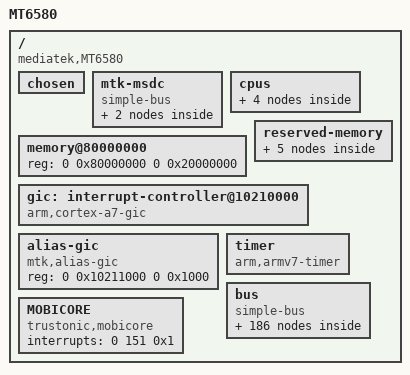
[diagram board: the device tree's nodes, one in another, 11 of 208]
/*
 * Mediatek's MT6580 SoC device tree source
 *
 * Copyright (c) 2013 MediaTek Co., Ltd.
 *              http://www.mediatek.com
 *
 */



/ {
	model = "MT6580";
	compatible = "mediatek,MT6580";
	interrupt-parent = <&gic>;
	#address-cells = <2>;
	#size-cells = <2>;

    /* chosen */
    chosen {
        bootargs = "console=tty0 console=ttyMT0,921600n1 root=/dev/ram initrd=0x84000000,0x400000 loglevel=8";
    };

    /* Do not put any bus before mtk-msdc, because it should be mtk-msdc.0 for partition device node usage */
    mtk-msdc {
        compatible = "simple-bus";
        #address-cells = <1>;
        #size-cells = <1>;
        ranges = <0 0 0 0xffffffff>;

        MSDC0@0x11120000 {
            compatible = "mediatek,MSDC0";
            reg = <0x11120000 0x10000  /* MSDC0_BASE   */
                   0x10001E84 0x2>;    /* FPGA PWR_GPIO, PWR_GPIO_EO */
            interrupts = <0 38 0x8>;
        };

        MSDC1@0x11130000 {
            compatible = "mediatek,MSDC1";
            reg = <0x11130000 0x10000  /* MSDC1_BASE   */
                   0x10001E84 0x2>;    /* FPGA PWR_GPIO, PWR_GPIO_EO */
            interrupts = <0 39 0x8>;
        };
    };

    cpus {
        #address-cells = <1>;
        #size-cells = <0>;

        cpu0: cpu@0 {
            device_type = "cpu";
            compatible = "arm,cortex-a7";
            reg = <0x000>;
            clock-frequency = <1700000000>;
        };

        cpu1: cpu@1 {
            device_type = "cpu";
            compatible = "arm,cortex-a7";
            reg = <0x001>;
            clock-frequency = <1700000000>;
        };

        cpu2: cpu@2 {
            device_type = "cpu";
            compatible = "arm,cortex-a7";
            reg = <0x002>;
            clock-frequency = <1700000000>;
        };

        cpu3: cpu@3 {
            device_type = "cpu";
            compatible = "arm,cortex-a7";
            reg = <0x003>;
            clock-frequency = <1700000000>;
        };
    };

    memory@80000000 {
        device_type = "memory";
        reg = <0 0x80000000 0 0x20000000>;
    };

    reserved-memory {
        #address-cells = <2>;
        #size-cells = <2>;
        ranges;

        reserve-memory-ccci_md1 {
            compatible = "reserve-memory-ccci_md1";
            no-map;
            size = <0 0x1800000>;       /* MD ROM + RAM + SMEM */
            alignment = <0 0x2000000>;  /* 32M alignment */
            alloc-ranges = <0 0x80000000 0 0x80000000>;
        };

        pstore-reserved-memory {
            compatible = "pstore-reserve-memory";
            reg = <0 0x83f10000 0 0xe0000>;
        };

		mrdump-reserved-memory {
			compatible = "mrdump-reserved-memory";
			reg = <0 0x81F00000 0 0x2000>;
		};

		preloader-reserved-memory {
			compatible = "mrdump-reserved-memory";
			reg = <0 0x82000000 0 0x200000>;
		};

		lk-reserved-memory {
			compatible = "mrdump-reserved-memory";
			reg = <0 0x81E00000 0 0x100000>;
		};
    };

    gic: interrupt-controller@10210000 {
        compatible = "arm,cortex-a7-gic";
        #interrupt-cells = <3>;
        #address-cells = <0>;
        interrupt-controller;
        reg = <0 0x10211000 0 0x1000>,
              <0 0x10212000 0 0x1000>,
              <0 0x10200100 0 0x1000>;
       interrupts = <1 9 0xf04>;
    };

    /* redundent gic device node to support other module's who want to use same query flow to get basic GIC info. EX: eint might want to know max GIC nr by */
    alias-gic {
        compatible = "mtk,alias-gic";
	reg = <0 0x10211000 0 0x1000>; /* only dist base is enough */
    };

    timer {
        compatible = "arm,armv7-timer";
        interrupts = <1 13 0x8>,
        <1 14 0x8>,
        <1 11 0x8>,
        <1 10 0x8>;
        clock-frequency = <13000000>;
    };

	bus {
		compatible = "simple-bus";
		#address-cells = <1>;
		#size-cells = <1>;
		ranges = <0 0 0 0xffffffff>;

		TOPCKGEN@0x10000000 {
			compatible = "mediatek,TOPCKGEN";
			reg = <0x10000000 0x1000>;
		};

		INFRACFG_AO@0x10001000 {
			compatible = "mediatek,INFRACFG_AO";
			reg = <0x10001000 0x1000>;
		};

        BAT_METTER {
            compatible = "mediatek,bat_meter";
        };
        
        BAT_NOTIFY {
            compatible = "mediatek,bat_notify";
        };

		BATTERY {
			compatible = "mediatek,battery";
		};


		KP@0x10002000 {
			compatible = "mediatek,KP";
			reg = <0x10002000 0x1000>;
			interrupts = <0 109 0x2>;
		};

		PERICFG@0x10003000 {
			compatible = "mediatek,PERICFG";
			reg = <0x10003000 0x1000>;
		};

		RESERVED@0x10004000 {
			compatible = "mediatek,RESERVED";
			reg = <0x10004000 0x1000>;
		};

		GPIO@0x10005000 {
			compatible = "mediatek,GPIO";
			reg = <0x10005000 0x1000>;
		};

		SLEEP@0x10006000 {
			compatible = "mediatek,SLEEP";
			reg = <0x10006000 0x1000>;
			interrupts = <0 88 0x8>,
				     <0 89 0x8>,
				     <0 90 0x8>,
				     <0 91 0x8>;
		};

		TOPRGU@0x10007000 {
			compatible = "mediatek,TOPRGU";
			reg = <0x10007000 0x1000>;
			interrupts = <0 157 0x2>;
		};

		APXGPT@0x10008000 {
			compatible = "mediatek,APXGPT";
			reg = <0x10008000 0x1000>;
			interrupts = <0 92 0x8>;
			clock-frequency = <13000000>;
		};

		EFUSEC@0x10009000 {
			compatible = "mediatek,EFUSEC";
			reg = <0x10009000 0x1000>;
		};

		SEJ@0x1000A000 {
			compatible = "mediatek,SEJ";
			reg = <0x1000A000 0x1000>;
			interrupts = <0 110 0x0>;
		};

		DBG_DEBUG {
			compatible = "mediatek,DBG_DEBUG";
			num = <4>;
			reg = <0x10170000 0x2000
				0x10172000 0x2000
				0x10174000 0x2000
				0x10176000 0x2000>;
                };

		eintc: EINTC@0x1000B000 {
			compatible = "mtk,mt-eic";
			reg = <0x1000B000 0x1000>;
			interrupts = <0 94 0x4>;

			#interrupt-cells = <2>;
			interrupt-controller;

			max_eint_num = <26>;
			mapping_table_entry = <83>;
			mapping_table = <0 0>, /* <gpio_pin, eint_pin> */
					<1 1>,
					<2 2>,
					<3 3>,
					<4 4>,
					<5 5>,
					<6 6>,
					<7 7>,
					<8 8>,
					<9 9>,
					<10 10>,
					<11 11>,
					<12 12>,
					<13 13>,
					<14 14>,
					<15 15>,
					<16 0>,
					<17 1>,
					<18 2>,
					<19 3>,
					<20 4>,
					<21 5>,
					<22 6>,
					<23 7>,
					<24 8>,
					<25 9>,
					<26 10>,
					<27 11>,
					<28 12>,
					<29 13>,
					<30 14>,
					<31 15>,
					<32 0>,
					<33 1>,
					<34 2>,
					<35 3>,
					<36 4>,
					<37 5>,
					<38 6>,
					<39 7>,
					<40 8>,
					<41 9>,
					<42 10>,
					<43 11>,
					<44 12>,
					<45 13>,
					<46 14>,
					<47 15>,
					<48 0>,
					<49 1>,
					<50 2>,
					<51 3>,
					<52 3>,
					<53 4>,
					<54 5>,
					<55 6>,
					<56 7>,
					<57 8>,
					<58 10>,
					<59 11>,
					<60 12>,
					<61 13>,
					<62 14>,
					<63 15>,
					<64 0>,
					<65 1>,
					<66 2>,
					<67 3>,
					<68 16>,
					<69 4>,
					<70 5>,
					<71 6>,
					<72 7>,
					<73 8>,
					<74 9>,
					<75 10>,
					<76 11>,
					<77 12>,
					<78 13>,
					<81 0>,
					<82 1>,
					<83 2>,
					<84 3>;

			/* the number of gpio/eint mapping might be affected by built-in eint */
			builtin_entry = <11>;
			/* gpio, built-in func mode, built-in eint */
			builtin_mapping = <0 3 20>, /* USB IDDIG & USB VBUS */
					   <1 3 18>,
					   <7 4 20>,
					   <8 4 18>,
					   <9 3 20>,
					   <10 3 18>,
					   <24 5 20>,
					   <25 5 18>,
					   <77 2 20>,
					   <78 2 18>,
					   <13 1 17>; /* PMIC */
		};

		AP_CCIF0@0x1000C000 {
			compatible = "mediatek,AP_CCIF0";
			reg = <0x1000C000 0x1000>,   /*AP_CCIF_BASE*/
				<0x1000D000 0x1000>; /*MD_CCIF_BASE*/
			interrupts = <0 93 0x8>,    /* CCIF0 IRQ */
				<0 152 0x2>;     /* MD WDT IRQ */
			ccif0,major = <184>;
			ccif0,minor_base = <0>;
			ccif0,capability = <2>;
			md_smem_size = <0x200000>; //md share memory size
		};

		MD_CCIF0@0x1000D000 {
			compatible = "mediatek,MD_CCIF0";
			reg = <0x1000D000 0x1000>;
		};

		MCUSYS_CFGREG@0x1020000 {
			compatible = "mediatek,MCUSYS_CFGREG_BASE";
			reg = <0x1020000 0x200>;
		};

		AP_MD_DBGMODE_CFGREG@0x1011A010 {
			compatible = "mediatek,AP_MD_DBGMODE_CFGREG";
			reg = <0x1011A010 0x200>;
		};

		AES@0x1000E000 {
			compatible = "mediatek,AES";
			reg = <0x1000E000 0x1000>;
		};

		PWRAP@0x1000F000 {
			compatible = "mediatek,PWRAP";
			reg = <0x1000F000 0x1000>;
			interrupts = <0 108 0x0>;
		};

		DEVAPC_AO@0x10010000 {
			compatible = "mediatek,DEVAPC_AO";
			reg = <0x10010000 0x1000>;
		};

		MIPI_CONFG@0x10011000 {
			compatible = "mediatek,MIPI_CONFG";
			reg = <0x10011000 0x1000>;
		};

		INFRA_MBIST@0x10012000 {
			compatible = "mediatek,INFRA_MBIST";
			reg = <0x10012000 0x1000>;
		};

		RESERVED@0x10013000 {
			compatible = "mediatek,RESERVED";
			reg = <0x10013000 0x1000>;
		};

		IOCFG_T@0x10014000 {
			compatible = "mediatek,IOCFG_T";
			reg = <0x10014000 0x1000>;
		};

		IOCFG_B@0x10015000 {
			compatible = "mediatek,IOCFG_B";
			reg = <0x10015000 0x1000>;
		};

		IOCFG_L@0x10016000 {
			compatible = "mediatek,IOCFG_L";
			reg = <0x10016000 0x1000>;
		};

		IOCFG_R@0x10017000 {
			compatible = "mediatek,IOCFG_R";
			reg = <0x10017000 0x1000>;
		};

		APMIXED@0x10018000 {
			compatible = "mediatek,APMIXED";
			reg = <0x10018000 0x1000>;
		};

		MCUCFG@0x10200000 {
			compatible = "mediatek,MCUCFG";
			reg = <0x10200000 0x1000>;
		};

		INFRACFG@0x10201000 {
			compatible = "mediatek,INFRACFG";
			reg = <0x10201000 0x1000>;
		};

                SYS_CIRQ@0x10202000 {
                        compatible = "mediatek,SYS_CIRQ";
                        reg = <0x10202000 0x1000>;
                        interrupts = <0 158 0x8>;
                        cirq_num = <126>;
                        spi_start_offset = <32>;
                };


		M4U@0x10203000 {
                        cell-index = <0>;
			compatible = "mediatek,M4U";
			reg = <0x10203000 0x1000>;
                        interrupts = <0 81 0x8>;
		};

		DEVAPC@0x10204000 {
			compatible = "mediatek,DEVAPC";
			reg = <0x10204000 0x1000>;
			interrupts = <0 74 0x8>;
		};

		EMI@0x10205000 {
			compatible = "mediatek,EMI";
			reg = <0x10205000 0x1000>;
			interrupts = <0 76 0x4>;
		};
		
		DRAMC_NAO@0x10206000 {
			compatible = "mediatek,DRAMC_NAO";
			reg = <0x10206000 0x1000>;
		};

		DRAMC0@0x10207000 {
			compatible = "mediatek,DRAMC0";
			reg = <0x10207000 0x1000>;
		};

		DDRPHY@0x10208000 {
			compatible = "mediatek,DDRPHY";
			reg = <0x10208000 0x1000>;
		};

		SRAMROM@0x10209000 {
			compatible = "mediatek,SRAMROM";
			reg = <0x10209000 0x1000>;
		};

		GCE@0x1020A000 {
			compatible = "mediatek,GCE";
			reg = <0x1020A000 0x1000>;
			interrupts = <0 85 0x8>,
			             <0 86 0x8>;
		};

		BUS_DBG@0x1020B000 {
			compatible = "mediatek,BUS_DBG";
			reg = <0x1020B000 0x1000>;
			interrupts = <0 73 0x8>;
			two_stage_timeout = <1>;
		};

		TRNG@0x1020C000 {
			compatible = "mediatek,TRNG";
			reg = <0x1020C000 0x1000>;
			interrupts = <0 87 0x8>;
		};

		MCUCFG_BIU@0x1020D000 {
			compatible = "mediatek,MCUCFG_BIU";
			reg = <0x1020D000 0x1000>;
		};


		DBGSYS_DEM@0x1011A000 {
			compatible = "mediatek,DBGSYS_DEM";
			reg = <0x1011A000 0x1000>;
		};

		DBGSYS_CTI@0x10112000 {
			compatible = "mediatek,DBGSYS_CTI";
			reg = <0x10112000 0x1000>;
		};

		DBGSYS_DAPROM@0x10110000 {
			compatible = "mediatek,DBGSYS_DAPROM";
			reg = <0x10110000 0x1000>;
		};

		DBGSYS_CPU@0x10160000 {
			compatible = "mediatek,DBGSYS_CPU";
			reg = <0x10160000 0x20000>;
		};

		DBGSYS_MDSYS@0x10120000 {
			compatible = "mediatek,DBGSYS_MDSYS";
			reg = <0x10120000 0x10000>;
		};
		CQDMA@0x1020AC00 {
			compatible = "mediatek,CQDMA";
			reg = <0x1020AC00 0x1000>;
			interrupts = <0 77 0x8>;
			nr_channel = <1>;
		};
		AP_DMA@0x11000000 {
			compatible = "mediatek,AP_DMA";
			reg = <0x11000000 0x1000>;
			interrupts = <0 48 0x8>;
		};

		NFI@0x11001000 {
			compatible = "mediatek,NFI";
			reg = <0x11001000 0x1000>;
			interrupts = <0 79 0x8>;
		};

		NFIECC@0x11002000 {
			compatible = "mediatek,NFIECC";
			reg = <0x11002000 0x1000>;
			interrupts = <0 78 0x8>;
		};

		AUXADC@0x11003000 {
			compatible = "mediatek,AUXADC";
			reg = <0x11003000 0x1000>;
			interrupts = <0 35 0x2>;
		};

		FHCTL@0x11004000 {
			compatible = "mediatek,FHCTL";
			reg = <0x11004000 0x1000>;
		};

		AP_UART0@0x11005000 {
            cell-index = <0>;
			compatible = "mediatek,AP_UART0";
			reg = <0x11005000 0x1000>;
			interrupts = <0 44 0x8>;
		};

		AP_UART1@0x11006000 {
            cell-index = <1>;
			compatible = "mediatek,AP_UART1";
			reg = <0x11006000 0x1000>;
			interrupts = <0 45 0x8>;
		};
	
        AP_DMA_UART0_TX@0x11000480 {
            compatible = "mediatek,AP_DMA_UART0_TX";
            reg = <0x11000480 0x80>;
            interrupts = <0 56 0x8>;
        };

        AP_DMA_UART0_RX@0x11000500 {
            compatible = "mediatek,AP_DMA_UART0_RX";
            reg = <0x11000500 0x80>;
            interrupts = <0 57 0x8>;
        };

        AP_DMA_UART1_TX@0x11000580 {
            compatible = "mediatek,AP_DMA_UART1_TX";
            reg = <0x11000580 0x80>;
            interrupts = <0 58 0x8>;
        };

        AP_DMA_UART1_RX@0x11000600 {
            compatible = "mediatek,AP_DMA_UART1_RX";
            reg = <0x11000600 0x80>;
            interrupts = <0 59 0x8>;
        };


		PWM@0x11008000 {
			compatible = "mediatek,PWM";
			reg = <0x11008000 0x1000>;
			interrupts = <0 36 0x8>;
		};

		i2c0: I2C0@0x11009000 {
			compatible = "mediatek,I2C0";
			cell-index = <0>;
			reg = <0x11009000 0x1000>;
			#address-cells = <1>;
			#size-cells = <0>;
			interrupts = <0 40 0x8>,
				<0 50 0x8>;
		};

		i2c1: I2C1@0x1100A000 {
			compatible = "mediatek,I2C1";
			cell-index = <1>;
			reg = <0x1100A000 0x1000>;
			#address-cells = <1>;
			#size-cells = <0>;
			interrupts = <0 41 0x8>,
				<0 51 0x8>;
		};

		i2c2: I2C2@0x1100B000 {
			compatible = "mediatek,I2C2";
			cell-index = <2>;
			reg = <0x1100B000 0x1000>;
			#address-cells = <1>;
			#size-cells = <0>;
			interrupts = <0 42 0x8>,
				<0 52 0x8>;
		};

		SPI@0x1100C000 {
			compatible = "mediatek,SPI";
			cell-index = <0>;
			spi-padmacro = <0>;
			/* spi-cs=<0 1>; */
			/* spi-clk=<1 1>; */
			/* spi-mo=<2 1>; */
			/* spi-mi=<3 1>; */
			reg = <0x1100C000 0x1000>;
			interrupts = <0 64 0x8>;
		};

		THERM_CTRL@0x1100D000 {
			compatible = "mediatek,THERM_CTRL";
			reg = <0x1100D000 0x1000>;
			interrupts = <0 37 0x8>;
		};


		AP_DMA_BTIF_TX@0x11000380 {
			compatible = "mediatek,AP_DMA_BTIF_TX";
			reg = <0x11000380 0x80>;
			interrupts = <0 54 0x8>;
		};

		AP_DMA_BTIF_RX@0x11000400 {
			compatible = "mediatek,AP_DMA_BTIF_RX";
			reg = <0x11000400 0x80>;
			interrupts = <0 55 0x8>;
		};

		BTIF@0x1100C000 {
			compatible = "mediatek,BTIF";
			reg = <0x1100E000 0x1000>;
			interrupts = <0 67 0x8>;
		};

		mt3326-gps@0xffffffff {
			compatible = "mediatek,mt3326-gps";
		};


		BTCVSD@0x18000000 {
			compatible = "mediatek,audio_bt_cvsd";
			reg = <0x18000000 0x1000>, /*CVSD REG_BASE*/
			      <0x18080000 0x1000>; /*CVSD SRAM*/
			interrupts = <0 153 0x8>;
		};

	    CONSYS@0x18070000 {
	        compatible = "mediatek,CONSYS";
	        reg = <0x18070000 0x0200>,  /*CONN_MCU_CONFIG_BASE      */
	              <0x10007000 0x0100>,  /*AP_RGU_BASE               */
	              <0x10000000 0x2000>,  /*TOPCKGEN_BASE             */
	              <0x10006000 0x1000>,  /*SPM_BASE                  */
	              <0x10005000 0x1000>;  /*DA_XOBUF                  */
		      interrupts = <0 154 0x8>, /*BGF_EINT                  */
		      			   <0 156 0x8>; /*WDT_EINT                  */
	    };

		WIFI@0x180F0000 {
			compatible = "mediatek,WIFI";
			reg = <0x180F0000 0x005C>;
			interrupts = <0 155 0x8>;
		};
		DISP_PWM@0x1100F000 {
			compatible = "mediatek,DISP_PWM";
			reg = <0x1100F000 0x1000>;
			interrupts = <0 33 0x8>;
		};

 		USB0@0x11100000 {
			compatible = "mediatek,USB0";
			cell-index = <0>;
			reg = <0x11100000 0x10000>,
						<0x11110000 0x10000>;
			interrupts = <0 32 0x8>;
			mode = <2>;
			multipoint = <1>;
			dyn_fifo = <1>;
			soft_con = <1>;
			dma = <1>;
			num_eps = <16>;
			dma_channels = <8>;
			iddig_gpio = <9 3>;
			drvvbus_gpio = <10 3>;
		};

		AUDIO@0x11140000 {
			compatible = "mediatek,AUDIO";
			reg = <0x11140000 0x10000>;
			interrupts = <0 80 0x8>;
		};
		
		MT_SOC_DL1_PCM@0x11140000 {
			compatible = "mediatek,mt_soc_pcm_dl1";
			reg = <0x11140000 0x1000>;
			interrupts = <0 80 0x8>;
			audclk-gpio = <26 0>;
			audmiso-gpio = <28 0>;
			audmosi-gpio = <27 0>;
		};

		MT_SOC_UL1_PCM@0x11140000 {
			compatible = "mediatek,mt_soc_pcm_capture";	
		};

		MT_SOC_VOICE_MD1@0x11140000 {
			compatible = "mediatek,mt_soc_pcm_voice_md1";	
		};

		MT_SOC_HDMI_PCM@0x11140000 {
			compatible = "mediatek,mt_soc_pcm_hdmi";	
		};

		MT_SOC_ULDLLOOPBACK_PCM@0x11140000 {
			compatible = "mediatek,mt_soc_pcm_uldlloopback";	
		};

		MT_SOC_I2S0_PCM@0x11140000 {
			compatible = "mediatek,mt_soc_pcm_dl1_i2s0";	
		};

		MT_SOC_MRGRX_PCM@0x11140000 {
			compatible = "mediatek,mt_soc_pcm_mrgrx";	
		};

		MT_SOC_MRGRX_AWB_PCM@0x11140000 {
			compatible = "mediatek,mt_soc_pcm_mrgrx_awb";	
		};

		MT_SOC_FM_I2S_PCM@0x11140000 {
			compatible = "mediatek,mt_soc_pcm_fm_i2s";	
		};

		MT_SOC_FM_I2S_AWB_PCM@0x11140000 {
			compatible = "mediatek,mt_soc_pcm_fm_i2s_awb";	
		};

		MT_SOC_I2S0DL1_PCM@0x11140000 {
			compatible = "mediatek,mt_soc_pcm_dl1_i2s0Dl1";	
		};	

		MT_SOC_DL1_AWB_PCM@0x11140000 {
			compatible = "mediatek,mt_soc_pcm_dl1_awb";	
		};

		MT_SOC_VOICE_MD1_BT@0x11140000 {
			compatible = "mediatek,mt_soc_pcm_voice_md1_bt";	
		};

		MT_SOC_VOIP_BT_OUT@0x11140000 {
			compatible = "mediatek,mt_soc_pcm_dl1_bt";	
		};

		MT_SOC_VOIP_BT_IN@0x11140000 {
			compatible = "mediatek,mt_soc_pcm_bt_dai";	
		};

		MT_SOC_TDMRX_PCM@0x11140000 {
			compatible = "mediatek,mt_soc_tdm_capture";	
		};

		MT_SOC_FM_MRGTX_PCM@0x11140000 {
			compatible = "mediatek,mt_soc_pcm_fmtx";	
		};

		MT_SOC_UL2_PCM@0x11140000 {
			compatible = "mediatek,mt_soc_pcm_capture2";	
		};

		MT_SOC_I2S0_AWB_PCM@0x11140000 {
			compatible = "mediatek,mt_soc_pcm_i2s0_awb";	
		};	

		MT_SOC_VOICE_MD2@0x11140000 {
			compatible = "mediatek,mt_soc_pcm_voice_md2";	
		};

		MT_SOC_ROUTING_PCM@0x11140000 {
			compatible = "mediatek,mt_soc_pcm_routing";	
		};

		MT_SOC_VOICE_MD2_BT@0x11140000 {
			compatible = "mediatek,mt_soc_pcm_voice_md2_bt";	
		};	

		MT_SOC_HP_IMPEDANCE_PCM@0x11140000 {
			compatible = "mediatek,Mt_soc_pcm_hp_impedance";	
		};		

		MT_SOC_CODEC_NAME@0x11140000 {
			compatible = "mediatek,mt_soc_codec_63xx";	
		};		

		MT_SOC_DUMMY_PCM@0x11140000 {
			compatible = "mediatek,mt_soc_pcm_dummy";	
		};

		MT_SOC_CODEC_DUMMY_NAME@0x11140000 {
			compatible = "mediatek,mt_soc_codec_dummy";	
		};

		MT_SOC_ROUTING_DAI_NAME@0x11140000 {
			compatible = "mediatek,mt_soc_dai_routing";	
		};

		MT_SOC_DAI_NAME@0x11140000 {
			compatible = "mediatek,mt_soc_dai_stub";	
		};
		
		AHB_MOM@0x11150000 {
			compatible = "mediatek,AHB_MOM";
			reg = <0x11150000 0x10000>;
		};

		MDI@0x11160000 {
			compatible = "mediatek,MDI";
			reg = <0x11160000 0x10000>;
		};

		G3D_CONFIG@0x13000000 {
			compatible = "mediatek,G3D_CONFIG";
			reg = <0x13000000 0x1000>;
		};

		MALI@0x13010000 {
			compatible = "mediatek,MALI";
			reg = <0x13010000 0x10000>;
		};

		MMSYS_CONFIG@0x14000000 {
			compatible = "mediatek,MMSYS_CONFIG";
			reg = <0x14000000 0x1000>;
			interrupts = <0 132 0x8>;
		};

		MDP_RDMA@0x14001000 {
			compatible = "mediatek,MDP_RDMA";
			reg = <0x14001000 0x1000>;
			interrupts = <0 113 0x8>;
		};

		MDP_RSZ0@0x14002000 {
			compatible = "mediatek,MDP_RSZ0";
			reg = <0x14002000 0x1000>;
			interrupts = <0 114 0x8>;
		};

		MDP_RSZ1@0x14003000 {
			compatible = "mediatek,MDP_RSZ1";
			reg = <0x14003000 0x1000>;
			interrupts = <0 115 0x8>;
		};

		MDP_WDMA@0x14004000 {
			compatible = "mediatek,MDP_WDMA";
			reg = <0x14004000 0x1000>;
			interrupts = <0 117 0x8>;
		};

		MDP_WROT@0x14005000 {
			compatible = "mediatek,MDP_WROT";
			reg = <0x14005000 0x1000>;
			interrupts = <0 118 0x8>;
		};

		MDP_TDSHP@0x14006000 {
			compatible = "mediatek,MDP_TDSHP";
			reg = <0x14006000 0x1000>;
			interrupts = <0 116 0x8>;
		};
		DISPSYS@0x14007000 {
			compatible = "mediatek,DISPSYS";
			reg = <0x14000000 0x1000>,  /*DISP_SYS     */
			      <0x14007000 0x1000>,  /*DISP_OVL0     */
			      <0x14008000 0x1000>,  /*DISP_OVL1     */
			      <0x14009000 0x1000>,  /*DISP_RDMA0     */
			      <0x1400A000 0x1000>,  /*DISP_RDMA1     */
			      <0x1400B000 0x1000>,  /*DISP_WDMA0     */
			      <0x1400C000 0x1000>,  /*DISP_COLOR     */
			      <0x1400D000 0x1000>,  /*DISP_CCORR     */
			      <0x1400E000 0x1000>,  /*DISP_AAL       */
			      <0x1400F000 0x1000>,  /*DISP_GAMMA     */
			      <0x14010000 0x1000>,  /*DISP_DITHER    */
			      <0x14011000 0x1000>,  /*DISP_UFOE      */
			      <0x14012000 0x1000>,  /*DISP_DSI0       */
			      <0x14013000 0x1000>,  /*DISP_DPI0      */
			      <0x1100F000 0x1000>,  /*DISP_PWM       */
			      <0x14015000 0x1000>,  /*DISP_MUTEX     */
			      <0x14016000 0x1000>,  /*DISP_SMI_LARB0 */
			      <0x14017000 0x1000>,  /*DISP_SMI_COMMOM*/
			      <0x14018000 0x1000>;      /*MIPITX0,real chip would use this:<0x14018000 0x1000>;*/


      interrupts = <0 0 8>, /*DISP_SYS */
                   <0 119 8>, /*DISP_OVL0 */
                   <0 0 8>, /*DISP_OVL1 */
                   <0 121 8>, /*DISP_RDMA0 */
                   <0 0 8>, /*DISP_RDMA1 */
                   <0 123 8>, /*DISP_WDMA0 */
                   <0 124 8>, /*DISP_COLOR */
                   <0 0 8>, /*DISP_CCORR */
                   <0 126 8>, /*DISP_AAL */
                   <0 127 8>, /*DISP_GAMMA */
                   <0 128 8>, /*DISP_DITHER */
                   <0 0 8>, /*DISP_UFOE */
                   <0 130 8>, /*DISP_DSI0 */
                   <0 0 8>, /*DISP_DPI0 */
                   <0 0 8>, /*DISP_PWM */
                   <0 112 8>, /*DISP_MUTEX */
                   <0 0 8>, /*DISP_SMI_LARB0 */
                   <0 0 8>, /*DISP_SMI_COMMOM*/
                   <0 0 8>; /*MIPITX0*/
        	};

		DISP_OVL0@0x14007000 {
			compatible = "mediatek,DISP_OVL0";
			reg = <0x14007000 0x1000>;
			interrupts = <0 119 0x8>;
		};

		DISP_OVL1@0x14008000 {
			compatible = "mediatek,DISP_OVL1";
			reg = <0x14008000 0x1000>;
		};

		DISP_RDMA0@0x14009000 {
			compatible = "mediatek,DISP_RDMA0";
			reg = <0x14009000 0x1000>;
			interrupts = <0 121 0x8>;
		};

		DISP_RDMA1@0x1400A000 {
			compatible = "mediatek,DISP_RDMA1";
			reg = <0x1400A000 0x1000>;
		};

		DISP_WDMA@0x1400B000 {
			compatible = "mediatek,DISP_WDMA";
			reg = <0x1400B000 0x1000>;
			interrupts = <0 123 0x8>;
		};

		DISP_COLOR@0x1400C000 {
			compatible = "mediatek,DISP_COLOR";
			reg = <0x1400C000 0x1000>;
			interrupts = <0 124 0x8>;
		};

		DISP_CCORR@0x1400D000 {
			compatible = "mediatek,DISP_CCORR";
			reg = <0x1400D000 0x1000>;
		};

		DISP_AAL@0x1400E000 {
			compatible = "mediatek,DISP_AAL";
			reg = <0x1400E000 0x1000>;
			interrupts = <0 126 0x8>;
		};

		DISP_GAMMA@0x1400F000 {
			compatible = "mediatek,DISP_GAMMA";
			reg = <0x1400F000 0x1000>;
			interrupts = <0 127 0x8>;
		};

		DISP_DITHER@0x14010000 {
			compatible = "mediatek,DISP_DITHER";
			reg = <0x14010000 0x1000>;
			interrupts = <0 128 0x8>;
		};

		DISP_UFOE@0x14011000 {
			compatible = "mediatek,DISP_UFOE";
			reg = <0x14011000 0x1000>;
		};

		DSI@0x14012000 {
			compatible = "mediatek,DSI";
			reg = <0x14012000 0x1000>;
		};

		DPI@0x14013000 {
			compatible = "mediatek,DPI";
			reg = <0x14013000 0x1000>;
		};

		
		PTP_FSM@0x1100D000 {
			compatible = "mediatek,PTP_FSM";
			reg = <0x1100D000 0x1000>;
			interrupts = <0 43 0x8>;
		};
		
		MM_MUTEX@0x14015000 {
			compatible = "mediatek,MM_MUTEX";
			reg = <0x14015000 0x1000>;
			interrupts = <0 112 0x8>;
		};

		SMI_LARB0@0x14016000 {
			compatible = "mediatek,SMI_LARB0";
			reg = <0x14016000 0x1000>;
			interrupts = <0 133 0x8>;
		};

		SMI_COMMON@0x14017000 {
			compatible = "mediatek,SMI_COMMON";
			reg = <0x14017000 0x1000>,  /* SMI_COMMON */
				<0x14016000 0x1000>,  /* LARB 0 */ 
				<0x15001000 0x1000>;  /* LARB 1 */
		};

		MIPI_TX_CONFIG@0x14018000 {
			compatible = "mediatek,MIPI_TX_CONFIG";
			reg = <0x14018000 0x1000>;
		};

                ISPSYS@0x15000000 {
			compatible = "mediatek,ISPSYS";
			reg = <0x15004000 0x9000>,  /*ISP_ADDR      */
				<0x15000000 0x10000>,  /*IMGSYS_CONFIG_ADDR      */
				<0x10011000 0x4000>,  /*MIPI_ANA_ADDR      */
				<0x10017000 0x1000>;
			interrupts = <0 142 0x8>, /* SENINF */
                                     <0 139 0x8>; /* CAM0 */
		};
                /*for sysram dev and pipemgr dev*/
                ISP_SYSR@0x15000000 {
			compatible = "mediatek,ISP_SYSR";
		};
                ISP_PIPEM@0x15000000 {
			compatible = "mediatek,ISP_PIPEM";
		};
		KD_CAMERA_HW1@0x15008000 {
                        compatible = "mediatek,CAMERA_HW";
                        reg = <0x15008000 0x1000>;  /* SENINF_ADDR */
                };
                KD_CAMERA_HW2@0x15008000 {
                        compatible = "mediatek,CAMERA_HW2";
                        reg = <0x15008000 0x1000>;  /* SENINF_ADDR */
                };
		SENINF_TOP@0x15008000 {
			compatible = "mediatek,SENINF_TOP";
			reg = <0x15008000 0x1000>;
			interrupts = <0 142 0x8>;
		};

		CAM_0@0x15004000 {
			compatible = "mediatek,CAM_0";
			reg = <0x15004000 0x1000>;
			interrupts = <0 139 0x8>;
		};

		CAM_1@0x15005000 {
			compatible = "mediatek,CAM_1";
			reg = <0x15005000 0x1000>;
		};

		VENC@0x15009000 {
			compatible = "mediatek,VENC";
			reg = <0x15009000 0x1000>;
			interrupts = <0 138 0x8>;
		};

		VDEC@0x1500B000 {
			compatible = "mediatek,VDEC";
			reg = <0x1500B000 0x1000>;
			interrupts = <0 137 0x8>;
		};

		SMI_LARB1@0x15001000 {
			compatible = "mediatek,SMI_LARB1";
			reg = <0x15001000 0x1000>;
			interrupts = <0 136 0x8>;
		};

		IMGSYS_CONFIG@0x15000000 {
			compatible = "mediatek,IMGSYS_CONFIG";
			reg = <0x15000000 0x1000>;
		};

		hwmsensor@0 {
			compatible = "mediatek,hwmsensor";
		};
		gsensor@0 {
			compatible = "mediatek,gsensor";
		};
		als_ps@0 {
			compatible = "mediatek,als_ps";
		};
		m_acc_pl@0 {
			compatible = "mediatek,m_acc_pl";
		};
		m_alsps_pl@0 {
			compatible = "mediatek,m_alsps_pl";
		};
		sensorHub@0 {
			compatible = "mediatek,sensorHub";
		};
		shf@0 {
			compatible = "mediatek,shf";
		};
		m_batch_pl@0 {
			compatible = "mediatek,m_batch_pl";
		};
		gyroscope@0 {
			compatible = "mediatek,gyroscope";
		};
		m_gyro_pl@0 {
			compatible = "mediatek,m_gyro_pl";
		};
		barometer@0 {
			compatible = "mediatek,barometer";
		};
		m_baro_pl@0 {
			compatible = "mediatek,m_baro_pl";
		};
		msensor@0 {
			compatible = "mediatek,msensor";
		};
		m_mag_pl@0 {
			compatible = "mediatek,m_mag_pl";
		};
		orientation@0 {
			compatible = "mediatek,orientation";
		};
		pedometer@0 {
			compatible = "mediatek,pedometer";
		};
		m_pdr_pl@0 {
			compatible = "mediatek,m_pdr_pl";
		};
		step_counter@0 {
			compatible = "mediatek,step_counter";
		};
		m_step_c_pl@0 {
			compatible = "mediatek,m_step_c_pl";
		};
		in_pocket@0 {
			compatible = "mediatek,in_pocket";
		};
		m_inpk_pl@0 {
			compatible = "mediatek,m_inpk_pl";
		};
		shake@0 {
			compatible = "mediatek,shake";
		};
		m_shk_pl@0 {
			compatible = "mediatek,m_shk_pl";
		};
		face_down@0 {
			compatible = "mediatek,face_down";
		};
		m_fdn_pl@0 {
			compatible = "mediatek,m_fdn_pl";
		};
		activity@0 {
			compatible = "mediatek,activity";
		};
		m_act_pl@0 {
			compatible = "mediatek,m_act_pl";
		};
		heart_rate@0 {
			compatible = "mediatek,heart_rate";
		};
		m_hrm_pl@0 {
			compatible = "mediatek,m_hrm_pl";
		};
		tilt_detector@0 {
			compatible = "mediatek,tilt_detector";
		};
		m_tilt_pl@0 {
			compatible = "mediatek,m_tilt_pl";
		};
		wake_gesture@0 {
			compatible = "mediatek,wake_gesture";
		};
		m_wag_pl@0 {
			compatible = "mediatek,m_wag_pl";
		};
		glance_gesture@0 {
			compatible = "mediatek,glance_gesture";
		};
		m_glg_pl@0 {
			compatible = "mediatek,m_glg_pl";
		};
		pick_up@0 {
			compatible = "mediatek,pick_up";
		};
		m_pkup_pl@0 {
			compatible = "mediatek,m_pkup_pl";
		};

        MTKFB@0 {
            compatible = "mediatek,MTKFB";
        };


	};

	MOBICORE {
		compatible = "trustonic,mobicore";
		interrupts = <0 151 0x1>;
	};

};

/include/ "cust_i2c.dtsi"
